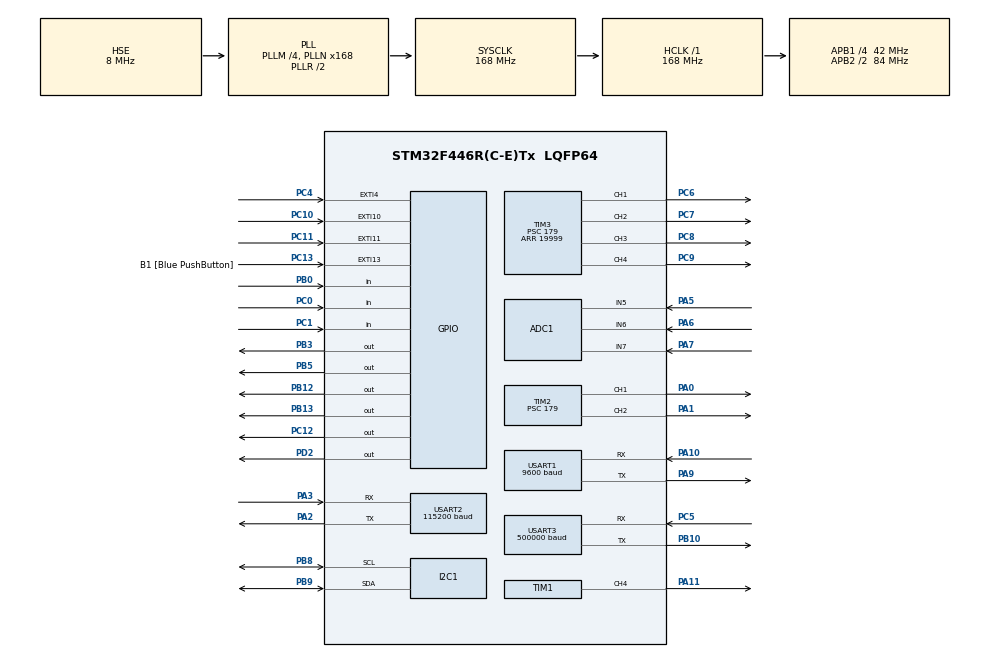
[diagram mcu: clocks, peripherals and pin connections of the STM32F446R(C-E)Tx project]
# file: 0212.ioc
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ADC1.Channel-4\#ChannelRegularConversion=ADC_CHANNEL_5
ADC1.Channel-7\#ChannelRegularConversion=ADC_CHANNEL_6
ADC1.Channel-8\#ChannelRegularConversion=ADC_CHANNEL_7
ADC1.ContinuousConvMode=ENABLE
ADC1.DMAContinuousRequests=ENABLE
ADC1.NbrOfConversion=3
ADC1.NbrOfConversionFlag=1
ADC1.Rank-7\#ChannelRegularConversion=2
ADC1.Rank-8\#ChannelRegularConversion=3
ADC1.SamplingTime-4\#ChannelRegularConversion=ADC_SAMPLETIME_3CYCLES
ADC1.SamplingTime-7\#ChannelRegularConversion=ADC_SAMPLETIME_3CYCLES
ADC1.SamplingTime-8\#ChannelRegularConversion=ADC_SAMPLETIME_3CYCLES
ADC1.ScanConvMode=ENABLE
ADC1.master=1
Dma.ADC1.0.Direction=DMA_PERIPH_TO_MEMORY
Dma.ADC1.0.FIFOMode=DMA_FIFOMODE_DISABLE
Dma.ADC1.0.Instance=DMA2_Stream0
Dma.ADC1.0.MemDataAlignment=DMA_MDATAALIGN_HALFWORD
Dma.ADC1.0.MemInc=DMA_MINC_ENABLE
Dma.ADC1.0.Mode=DMA_CIRCULAR
Dma.ADC1.0.PeriphDataAlignment=DMA_PDATAALIGN_HALFWORD
Dma.ADC1.0.PeriphInc=DMA_PINC_DISABLE
Dma.ADC1.0.Priority=DMA_PRIORITY_LOW
Dma.Request0=ADC1
Dma.Request1=USART1_RX
Dma.Request2=USART1_TX
Dma.Request3=USART2_TX
Dma.Request4=USART2_RX
Dma.USART1_RX.1.Direction=DMA_PERIPH_TO_MEMORY
Dma.USART1_RX.1.FIFOMode=DMA_FIFOMODE_DISABLE
Dma.USART1_RX.1.Instance=DMA2_Stream2
Dma.USART1_RX.1.MemDataAlignment=DMA_MDATAALIGN_BYTE
Dma.USART1_RX.1.MemInc=DMA_MINC_ENABLE
Dma.USART1_RX.1.Mode=DMA_CIRCULAR
Dma.USART1_RX.1.PeriphDataAlignment=DMA_PDATAALIGN_BYTE
Dma.USART1_RX.1.PeriphInc=DMA_PINC_DISABLE
Dma.USART1_RX.1.Priority=DMA_PRIORITY_HIGH
Dma.USART1_TX.2.Direction=DMA_MEMORY_TO_PERIPH
Dma.USART1_TX.2.FIFOMode=DMA_FIFOMODE_DISABLE
Dma.USART1_TX.2.Instance=DMA2_Stream7
Dma.USART1_TX.2.MemDataAlignment=DMA_MDATAALIGN_BYTE
Dma.USART1_TX.2.MemInc=DMA_MINC_ENABLE
Dma.USART1_TX.2.Mode=DMA_CIRCULAR
Dma.USART1_TX.2.PeriphDataAlignment=DMA_PDATAALIGN_BYTE
Dma.USART1_TX.2.PeriphInc=DMA_PINC_DISABLE
Dma.USART1_TX.2.Priority=DMA_PRIORITY_HIGH
Dma.USART2_RX.4.Direction=DMA_PERIPH_TO_MEMORY
Dma.USART2_RX.4.FIFOMode=DMA_FIFOMODE_DISABLE
Dma.USART2_RX.4.Instance=DMA1_Stream5
Dma.USART2_RX.4.MemDataAlignment=DMA_MDATAALIGN_BYTE
Dma.USART2_RX.4.MemInc=DMA_MINC_ENABLE
Dma.USART2_RX.4.Mode=DMA_CIRCULAR
Dma.USART2_RX.4.PeriphDataAlignment=DMA_PDATAALIGN_BYTE
Dma.USART2_RX.4.PeriphInc=DMA_PINC_DISABLE
Dma.USART2_RX.4.Priority=DMA_PRIORITY_HIGH
Dma.USART2_TX.3.Direction=DMA_MEMORY_TO_PERIPH
Dma.USART2_TX.3.FIFOMode=DMA_FIFOMODE_DISABLE
Dma.USART2_TX.3.Instance=DMA1_Stream6
Dma.USART2_TX.3.MemDataAlignment=DMA_MDATAALIGN_BYTE
Dma.USART2_TX.3.MemInc=DMA_MINC_ENABLE
Dma.USART2_TX.3.Mode=DMA_NORMAL
Dma.USART2_TX.3.PeriphDataAlignment=DMA_PDATAALIGN_BYTE
Dma.USART2_TX.3.PeriphInc=DMA_PINC_DISABLE
Dma.USART2_TX.3.Priority=DMA_PRIORITY_HIGH
Mcu.Family=STM32F4
Mcu.Name=STM32F446R(C-E)Tx
Mcu.Package=LQFP64
NVIC.DMA1_Stream5_IRQn=true\:0\:0\:false\:false\:true\:false\:true\:true
NVIC.DMA1_Stream6_IRQn=true\:0\:0\:false\:false\:true\:false\:true\:true
NVIC.DMA2_Stream0_IRQn=true\:0\:0\:false\:false\:true\:false\:true\:true
NVIC.DMA2_Stream2_IRQn=true\:0\:0\:false\:false\:true\:false\:true\:true
NVIC.DMA2_Stream7_IRQn=true\:0\:0\:false\:false\:true\:false\:true\:true
NVIC.EXTI15_10_IRQn=true\:0\:0\:false\:false\:true\:true\:true\:true
NVIC.EXTI4_IRQn=true\:0\:0\:false\:false\:true\:true\:true\:true
NVIC.I2C1_ER_IRQn=true\:0\:0\:false\:false\:true\:true\:true\:true
NVIC.I2C1_EV_IRQn=true\:0\:0\:false\:false\:true\:true\:true\:true
NVIC.PriorityGroup=NVIC_PRIORITYGROUP_0
NVIC.RCC_IRQn=true\:0\:0\:false\:false\:true\:true\:false\:true
NVIC.TIM1_BRK_TIM9_IRQn=true\:0\:0\:false\:false\:true\:true\:true\:true
NVIC.TIM1_CC_IRQn=true\:0\:0\:false\:false\:true\:true\:true\:true
NVIC.TIM1_TRG_COM_TIM11_IRQn=true\:0\:0\:false\:false\:true\:true\:true\:true
NVIC.TIM1_UP_TIM10_IRQn=true\:0\:0\:false\:false\:true\:true\:true\:true
NVIC.TIM6_DAC_IRQn=true\:0\:0\:false\:false\:true\:true\:true\:true
NVIC.TIM7_IRQn=true\:0\:0\:false\:false\:true\:true\:true\:true
NVIC.TIM8_UP_TIM13_IRQn=true\:0\:0\:false\:false\:true\:true\:true\:true
NVIC.USART1_IRQn=true\:0\:0\:false\:false\:true\:true\:true\:true
NVIC.USART2_IRQn=true\:0\:0\:false\:false\:true\:true\:true\:true
PA0-WKUP.Signal=S_TIM2_CH1_ETR
PA1.Signal=S_TIM2_CH2
PA10.Mode=Asynchronous
PA10.Signal=USART1_RX
PA11.Signal=S_TIM1_CH4
PA13.Signal=SYS_JTMS-SWDIO
PA14.GPIO_Label=TCK
PA14.Signal=SYS_JTCK-SWCLK
PA2.Mode=Asynchronous
PA2.Signal=USART2_TX
PA3.Mode=Asynchronous
PA3.Signal=USART2_RX
PA5.Signal=SharedAnalog_PA5
PA6.Signal=SharedAnalog_PA6
PA7.Signal=SharedAnalog_PA7
PA9.Mode=Asynchronous
PA9.Signal=USART1_TX
PB0.Signal=GPIO_Input
PB10.Mode=Asynchronous
PB10.Signal=USART3_TX
PB12.Signal=GPIO_Output
PB13.Signal=GPIO_Output
PB3.Signal=GPIO_Output
PB5.Signal=GPIO_Output
PB8.Mode=I2C
PB8.Signal=I2C1_SCL
PB9.Mode=I2C
PB9.Signal=I2C1_SDA
PC0.Signal=GPIO_Input
PC1.Signal=GPIO_Input
PC10.GPIO_ModeDefaultEXTI=GPIO_MODE_IT_RISING
PC10.Signal=GPXTI10
PC11.GPIO_ModeDefaultEXTI=GPIO_MODE_IT_RISING
PC11.Signal=GPXTI11
PC12.Signal=GPIO_Output
PC13.GPIO_Label=B1 [Blue PushButton]
PC13.GPIO_ModeDefaultEXTI=GPIO_MODE_IT_FALLING
PC13.Signal=GPXTI13
PC14-OSC32_IN.Mode=LSE-External-Oscillator
PC14-OSC32_IN.Signal=RCC_OSC32_IN
PC15-OSC32_OUT.Mode=LSE-External-Oscillator
PC15-OSC32_OUT.Signal=RCC_OSC32_OUT
PC4.Signal=GPXTI4
PC5.Mode=Asynchronous
PC5.Signal=USART3_RX
PC6.Signal=S_TIM3_CH1
PC7.Signal=S_TIM3_CH2
PC8.Signal=S_TIM3_CH3
PC9.Signal=S_TIM3_CH4
PD2.Signal=GPIO_Output
PH0-OSC_IN.Mode=HSE-External-Clock-Source
PH0-OSC_IN.Signal=RCC_OSC_IN
PH1-OSC_OUT.Mode=HSE-External-Clock-Source
PH1-OSC_OUT.Signal=RCC_OSC_OUT
ProjectManager.HeapSize=0x200
ProjectManager.StackSize=0x400
ProjectManager.TargetToolchain=STM32CubeIDE
RCC.48MHZClocksFreq_Value=84000000
RCC.AHBFreq_Value=168000000
RCC.APB1CLKDivider=RCC_HCLK_DIV4
RCC.APB1Freq_Value=42000000
RCC.APB1TimFreq_Value=84000000
RCC.APB2CLKDivider=RCC_HCLK_DIV2
RCC.APB2Freq_Value=84000000
RCC.APB2TimFreq_Value=168000000
RCC.CortexFreq_Value=168000000
RCC.FLatency-AdvancedSettings=FLASH_LATENCY_5
RCC.HCLKFreq_Value=168000000
RCC.HSE_VALUE=8000000
RCC.HSI_VALUE=16000000
RCC.PLLI2SM=2
RCC.PLLI2SN=50
RCC.PLLM=4
RCC.PLLN=168
RCC.PLLSAIM=2
RCC.PLLSAIN=50
RCC.PLLSourceVirtual=RCC_PLLSOURCE_HSE
RCC.SYSCLKFreq_VALUE=168000000
RCC.SYSCLKSource=RCC_SYSCLKSOURCE_PLLRCLK
RCC.USBFreq_Value=168000000
RCC.VCOOutputFreq_Value=336000000
SH.S_TIM1_CH4.0=TIM1_CH4,PWM Generation4 CH4
SH.S_TIM2_CH1_ETR.0=TIM2_CH1,PWM Generation1 CH1
SH.S_TIM2_CH2.0=TIM2_CH2,PWM Generation2 CH2
SH.S_TIM3_CH1.0=TIM3_CH1,PWM Generation1 CH1
SH.S_TIM3_CH2.0=TIM3_CH2,PWM Generation2 CH2
SH.S_TIM3_CH3.0=TIM3_CH3,PWM Generation3 CH3
SH.S_TIM3_CH4.0=TIM3_CH4,PWM Generation4 CH4
SH.SharedAnalog_PA5.0=GPIO_Analog
SH.SharedAnalog_PA5.1=ADC1_IN5,IN5
SH.SharedAnalog_PA6.0=GPIO_Analog
SH.SharedAnalog_PA6.1=ADC1_IN6,IN6
SH.SharedAnalog_PA7.0=GPIO_Analog
SH.SharedAnalog_PA7.1=ADC1_IN7,IN7
TIM1.Channel-PWM\ Generation4\ CH4=TIM_CHANNEL_4
TIM1.Period=19999
TIM1.Prescaler=167
TIM10.Period=9999
TIM10.Prescaler=167
TIM11.Period=99
TIM11.Prescaler=63
TIM13.Period=999
TIM13.Prescaler=167
TIM2.Channel-PWM\ Generation1\ CH1=TIM_CHANNEL_1
TIM2.Channel-PWM\ Generation2\ CH2=TIM_CHANNEL_2
TIM2.Period=19999
TIM2.Prescaler=179
TIM3.Channel-PWM\ Generation1\ CH1=TIM_CHANNEL_1
TIM3.Channel-PWM\ Generation2\ CH2=TIM_CHANNEL_2
TIM3.Channel-PWM\ Generation3\ CH3=TIM_CHANNEL_3
TIM3.Channel-PWM\ Generation4\ CH4=TIM_CHANNEL_4
TIM3.Period=19999
TIM3.Prescaler=179
TIM6.Period=1000
TIM6.Prescaler=120
TIM7.Period=500
TIM7.Prescaler=167
TIM8.Period=99
TIM8.Prescaler=63
USART1.BaudRate=9600
USART1.VirtualMode=VM_ASYNC
USART2.BaudRate=115200
USART2.VirtualMode=VM_ASYNC
USART3.BaudRate=500000
USART3.VirtualMode=VM_ASYNC
VP_TIM10_VS_ClockSourceINT.Mode=Enable_Timer
VP_TIM11_VS_ClockSourceINT.Mode=Enable_Timer
VP_TIM13_VS_ClockSourceINT.Mode=Enable_Timer
VP_TIM6_VS_ClockSourceINT.Mode=Enable_Timer
VP_TIM7_VS_ClockSourceINT.Mode=Enable_Timer
VP_TIM8_VS_ClockSourceINT.Mode=Internal
board=NUCLEO-F446RE

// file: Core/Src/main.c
/* USER CODE BEGIN Header */
/**
 ******************************************************************************
 * @file           : main.c
 * @brief          : Main program body
 ******************************************************************************
 * @attention
 *
 * Copyright (c) 2023 STMicroelectronics.
 * All rights reserved.
 *
 * This software is licensed under terms that can be found in the LICENSE file
 * in the root directory of this software component.
 * If no LICENSE file comes with this software, it is provided AS-IS.
 *
 ******************************************************************************
 */
/* USER CODE END Header */
#include "main.h"
#include "adc.h"
#include "dma.h"
#include "i2c.h"
#include "tim.h"
#include "usart.h"
#include "gpio.h"

/* USER CODE BEGIN Includes */
#include "mainpp.h"
#include "mainrun.h"
/* USER CODE END Includes */

void SystemClock_Config(void);

int main(void)
{

  /* MCU Configuration--------------------------------------------------------*/

  /* Reset of all peripherals, Initializes the Flash interface and the Systick. */
  HAL_Init();

  /* Configure the system clock */
  SystemClock_Config();

  /* Initialize all configured peripherals */
  MX_GPIO_Init();
  MX_DMA_Init();
  MX_USART3_UART_Init();
  MX_TIM3_Init();
  MX_ADC1_Init();
  MX_TIM6_Init();
  MX_TIM2_Init();
  MX_TIM7_Init();
  MX_USART1_UART_Init();
  MX_USART2_UART_Init();
  MX_TIM10_Init();
  MX_TIM11_Init();
  MX_I2C1_Init();
  MX_TIM13_Init();
  MX_TIM8_Init();
  MX_TIM1_Init();
  /* USER CODE BEGIN 2 */
	// DMA_init is in front of ADC
	setup();
	mainrun();

  /* USER CODE END 2 */

  /* Infinite loop */
	while (1) {

	}
}

void SystemClock_Config(void)
{
  RCC_OscInitTypeDef RCC_OscInitStruct = {0};
  RCC_ClkInitTypeDef RCC_ClkInitStruct = {0};

  /** Configure the main internal regulator output voltage
  */
  __HAL_RCC_PWR_CLK_ENABLE();
  __HAL_PWR_VOLTAGESCALING_CONFIG(PWR_REGULATOR_VOLTAGE_SCALE1);

  /** Initializes the RCC Oscillators according to the specified parameters
  * in the RCC_OscInitTypeDef structure.
  */
  RCC_OscInitStruct.OscillatorType = RCC_OSCILLATORTYPE_HSE;
  RCC_OscInitStruct.HSEState = RCC_HSE_BYPASS;
  RCC_OscInitStruct.PLL.PLLState = RCC_PLL_ON;
  RCC_OscInitStruct.PLL.PLLSource = RCC_PLLSOURCE_HSE;
  RCC_OscInitStruct.PLL.PLLM = 4;
  RCC_OscInitStruct.PLL.PLLN = 168;
  RCC_OscInitStruct.PLL.PLLP = RCC_PLLP_DIV2;
  RCC_OscInitStruct.PLL.PLLQ = 2;
  RCC_OscInitStruct.PLL.PLLR = 2;
  if (HAL_RCC_OscConfig(&RCC_OscInitStruct) != HAL_OK)
  {
    Error_Handler();
  }

  /** Initializes the CPU, AHB and APB buses clocks
  */
  RCC_ClkInitStruct.ClockType = RCC_CLOCKTYPE_HCLK|RCC_CLOCKTYPE_SYSCLK
                              |RCC_CLOCKTYPE_PCLK1|RCC_CLOCKTYPE_PCLK2;
  RCC_ClkInitStruct.SYSCLKSource = RCC_SYSCLKSOURCE_PLLRCLK;
  RCC_ClkInitStruct.AHBCLKDivider = RCC_SYSCLK_DIV1;
  RCC_ClkInitStruct.APB1CLKDivider = RCC_HCLK_DIV4;
  RCC_ClkInitStruct.APB2CLKDivider = RCC_HCLK_DIV2;

  if (HAL_RCC_ClockConfig(&RCC_ClkInitStruct, FLASH_LATENCY_5) != HAL_OK)
  {
    Error_Handler();
  }
}

void Error_Handler(void)
{
	__disable_irq();
	while (1) {
	}
}
